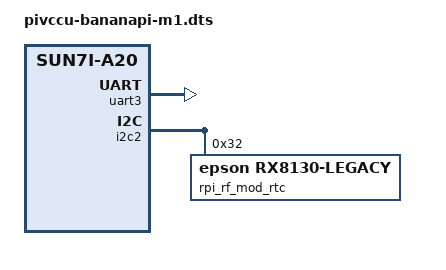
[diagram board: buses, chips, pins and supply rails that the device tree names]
/dts-v1/;
/plugin/;

/ {
  compatible = "allwinner,sun7i-a20";

  fragment@0 {
    target = <&uart3>;
    __overlay__ {
      status = "okay";
      compatible = "pivccu,dw_apb";
      pivccu,reset-gpios = <&pio 7 2 0>;
      pivccu,rtc = <&rpi_rf_mod_rtc>;
    };
  };

  fragment@1 {
    target = <&i2c2>;
    __overlay__ {
      #address-cells = <1>;
      #size-cells = <0>;
      status = "okay";

      rpi_rf_mod_rtc: rx8130@32 {
        compatible = "epson,rx8130-legacy";
        reg = <0x32>;
        status = "okay";
        aux-voltage-chargeable = <1>;
        enable-external-capacitor;
      };
    };
  };
};

